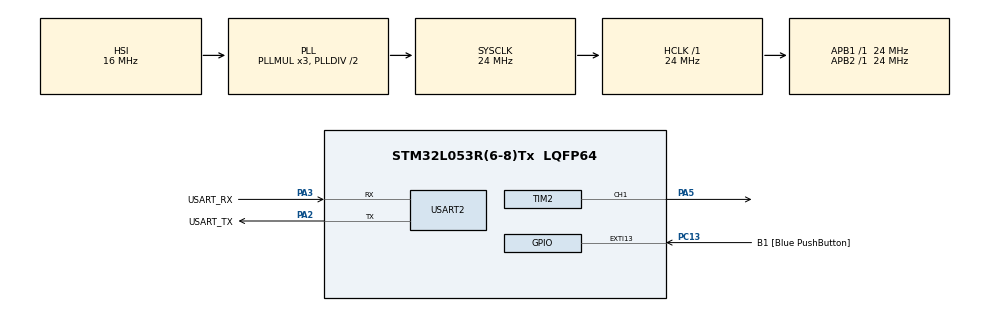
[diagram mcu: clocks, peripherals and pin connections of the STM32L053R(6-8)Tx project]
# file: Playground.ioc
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Mcu.Family=STM32L0
Mcu.Name=STM32L053R(6-8)Tx
Mcu.Package=LQFP64
NVIC.TIM21_IRQn=true\:0\:0\:false\:false\:true\:true\:true\:true
PA13.GPIO_Label=TMS
PA13.Mode=Serial_Wire
PA13.Signal=SYS_SWDIO
PA14.GPIO_Label=TCK
PA14.Mode=Serial_Wire
PA14.Signal=SYS_SWCLK
PA2.GPIO_Label=USART_TX
PA2.Mode=Asynchronous
PA2.Signal=USART2_TX
PA3.GPIO_Label=USART_RX
PA3.Mode=Asynchronous
PA3.Signal=USART2_RX
PA5.Signal=S_TIM2_CH1
PC13.GPIO_Label=B1 [Blue PushButton]
PC13.GPIO_ModeDefaultEXTI=GPIO_MODE_IT_FALLING
PC13.Signal=GPXTI13
PC14-OSC32_IN.Mode=LSE-External-Oscillator
PC14-OSC32_IN.Signal=RCC_OSC32_IN
PC15-OSC32_OUT.Mode=LSE-External-Oscillator
PC15-OSC32_OUT.Signal=RCC_OSC32_OUT
PH0-OSC_IN.Mode=HSE-External-Clock-Source
PH0-OSC_IN.Signal=RCC_OSC_IN
PH1-OSC_OUT.Signal=RCC_OSC_OUT
ProjectManager.HeapSize=0x200
ProjectManager.StackSize=0x400
ProjectManager.TargetToolchain=STM32CubeIDE
RCC.AHBFreq_Value=24000000
RCC.APB1Freq_Value=24000000
RCC.APB1TimFreq_Value=24000000
RCC.APB2Freq_Value=24000000
RCC.APB2TimFreq_Value=24000000
RCC.HCLKFreq_Value=24000000
RCC.HSE_VALUE=8000000
RCC.HSI16_VALUE=16000000
RCC.HSI48_VALUE=48000000
RCC.HSI_VALUE=16000000
RCC.MSI_VALUE=2097000
RCC.SYSCLKFreq_VALUE=24000000
RCC.SYSCLKSource=RCC_SYSCLKSOURCE_PLLCLK
RCC.VCOOutputFreq_Value=48000000
SH.S_TIM2_CH1.0=TIM2_CH1,PWM Generation1 CH1
TIM2.Channel-PWM\ Generation1\ CH1=TIM_CHANNEL_1
TIM2.Period=2399
TIM21.Period=23999
USART2.VirtualMode-Asynchronous=VM_ASYNC
VP_TIM21_VS_ClockSourceINT.Mode=Internal
VP_TIM2_VS_ClockSourceINT.Mode=Internal
board=NUCLEO-L053R8

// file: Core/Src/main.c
/* USER CODE BEGIN Header */
/**
  ******************************************************************************
  * @file           : main.c
  * @brief          : Main program body
  ******************************************************************************
  * @attention
  *
  * Copyright (c) 2024 STMicroelectronics.
  * All rights reserved.
  *
  * This software is licensed under terms that can be found in the LICENSE file
  * in the root directory of this software component.
  * If no LICENSE file comes with this software, it is provided AS-IS.
  *
  ******************************************************************************
  */
/* USER CODE END Header */
#include "main.h"
#include "tim.h"
#include "usart.h"
#include "gpio.h"

void SystemClock_Config(void);

int main(void)
{

  /* MCU Configuration--------------------------------------------------------*/

  /* Reset of all peripherals, Initializes the Flash interface and the Systick. */
  HAL_Init();

  /* Configure the system clock */
  SystemClock_Config();

  /* Initialize all configured peripherals */
  MX_GPIO_Init();
  MX_USART2_UART_Init();
  MX_TIM2_Init();
  MX_TIM21_Init();

  /* USER CODE BEGIN 2 */
  HAL_TIM_Base_Start_IT(&htim21); /* tim21 Start */

  /* USER CODE END 2 */

  /* Infinite loop */
  while (1)
  {

  }
}

void SystemClock_Config(void)
{
  RCC_OscInitTypeDef RCC_OscInitStruct = {0};
  RCC_ClkInitTypeDef RCC_ClkInitStruct = {0};
  RCC_PeriphCLKInitTypeDef PeriphClkInit = {0};

  /** Configure the main internal regulator output voltage
  */
  __HAL_PWR_VOLTAGESCALING_CONFIG(PWR_REGULATOR_VOLTAGE_SCALE1);

  /** Initializes the RCC Oscillators according to the specified parameters
  * in the RCC_OscInitTypeDef structure.
  */
  RCC_OscInitStruct.OscillatorType = RCC_OSCILLATORTYPE_HSI;
  RCC_OscInitStruct.HSIState = RCC_HSI_ON;
  RCC_OscInitStruct.HSICalibrationValue = RCC_HSICALIBRATION_DEFAULT;
  RCC_OscInitStruct.PLL.PLLState = RCC_PLL_ON;
  RCC_OscInitStruct.PLL.PLLSource = RCC_PLLSOURCE_HSI;
  RCC_OscInitStruct.PLL.PLLMUL = RCC_PLLMUL_3;
  RCC_OscInitStruct.PLL.PLLDIV = RCC_PLLDIV_2;
  if (HAL_RCC_OscConfig(&RCC_OscInitStruct) != HAL_OK)
  {
    Error_Handler();
  }

  /** Initializes the CPU, AHB and APB buses clocks
  */
  RCC_ClkInitStruct.ClockType = RCC_CLOCKTYPE_HCLK|RCC_CLOCKTYPE_SYSCLK
                              |RCC_CLOCKTYPE_PCLK1|RCC_CLOCKTYPE_PCLK2;
  RCC_ClkInitStruct.SYSCLKSource = RCC_SYSCLKSOURCE_PLLCLK;
  RCC_ClkInitStruct.AHBCLKDivider = RCC_SYSCLK_DIV1;
  RCC_ClkInitStruct.APB1CLKDivider = RCC_HCLK_DIV1;
  RCC_ClkInitStruct.APB2CLKDivider = RCC_HCLK_DIV1;

  if (HAL_RCC_ClockConfig(&RCC_ClkInitStruct, FLASH_LATENCY_1) != HAL_OK)
  {
    Error_Handler();
  }
  PeriphClkInit.PeriphClockSelection = RCC_PERIPHCLK_USART2;
  PeriphClkInit.Usart2ClockSelection = RCC_USART2CLKSOURCE_PCLK1;
  if (HAL_RCCEx_PeriphCLKConfig(&PeriphClkInit) != HAL_OK)
  {
    Error_Handler();
  }
}

void Error_Handler(void)
{
  __disable_irq();
  while (1)
  {
  }
}
